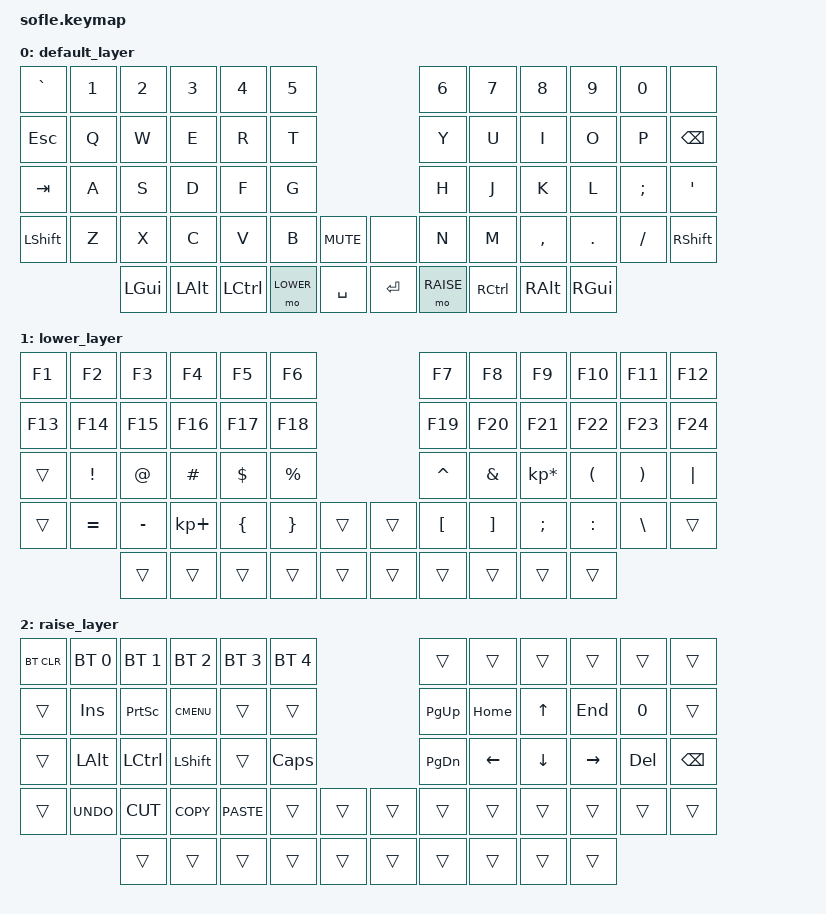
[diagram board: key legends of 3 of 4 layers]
/*
* Copyright (c) 2020 The ZMK Contributors
*
* SPDX-License-Identifier: MIT
*/

#include <behaviors.dtsi>
#include <dt-bindings/zmk/bt.h>
#include <dt-bindings/zmk/ext_power.h>
#include <dt-bindings/zmk/keys.h>
#include <dt-bindings/zmk/rgb.h>

#define BASE 0
#define LOWER 1
#define RAISE 2
#define ADJUST 3

/ {
    // Activate ADJUST layer by pressing raise and lower

    conditional_layers {
        compatible = "zmk,conditional-layers";

        adjust_layer {
            if-layers = <LOWER RAISE>;
            then-layer = <ADJUST>;
        };
    };

    keymap {
        compatible = "zmk,keymap";

        default_layer {
            // ------------------------------------------------------------------------------------------------------------
            // |  `    |  1  |  2  |  3   |  4   |  5   |                   |  6   |  7    |  8    |  9   |   0   |       |
            // |  ESC  |  Q  |  W  |  E   |  R   |  T   |                   |  Y   |  U    |  I    |  O   |   P   | BKSPC |
            // |  TAB  |  A  |  S  |  D   |  F   |  G   |                   |  H   |  J    |  K    |  L   |   ;   |   '   |
            // | SHIFT |  Z  |  X  |  C   |  V   |  B   |  MUTE  |  |       |  N   |  M    |  ,    |  .   |   /   | SHIFT |
            //               | GUI | ALT  | CTRL | LOWER|  ENTER |  | SPACE | RAISE| CTRL  | ALT   | GUI  |

            bindings = <
&kp GRAVE  &kp N1  &kp N2    &kp N3    &kp N4     &kp N5                              &kp N6     &kp N7     &kp N8     &kp N9    &kp N0    &none
&kp ESC    &kp Q   &kp W     &kp E     &kp R      &kp T                               &kp Y      &kp U      &kp I      &kp O     &kp P     &kp BSPC
&kp TAB    &kp A   &kp S     &kp D     &kp F      &kp G                               &kp H      &kp J      &kp K      &kp L     &kp SEMI  &kp SQT
&kp LSHFT  &kp Z   &kp X     &kp C     &kp V      &kp B      &kp C_MUTE    &none      &kp N      &kp M      &kp COMMA  &kp DOT   &kp FSLH  &kp RSHFT
                   &kp LGUI  &kp LALT  &kp LCTRL  &mo LOWER  &kp SPACE     &kp ENTER  &mo RAISE  &kp RCTRL  &kp RALT   &kp RGUI
            >;

            sensor-bindings = <&inc_dec_kp C_VOL_UP C_VOL_DN &inc_dec_kp PG_UP PG_DN>;
        };

        lower_layer {
            // TODO: Some binds are waiting for shifted keycode support.
            // ------------------------------------------------------------------------------------------------------------
            // |  F1   |  F2 |  F3 |  F4  |  F5  |  F6  |                   |  F7  |  F8   |  F9   |  F10 |  F11  |  F12  |
            // |  F13  | F14 | F15 | F16  | F17  | F18  |                   | F19  |  F20  |  F21  |  F22 |  F23  |  F24  |
            // |       |  !  |  @  |  #   |  $   |  %   |                   |  ^   |  &    |  *    |  (   |   )   |   |   |
            // |       |  =  |  -  |  +   |  {   |  }   |        |  |       |  [   |  ]    |  ;    |  :   |   \   |       |
            //               |     |      |      |      |        |  |       |      |       |       |      |

            bindings = <
&kp F1   &kp F2     &kp F3     &kp F4       &kp F5    &kp F6                       &kp F7     &kp F8    &kp F9           &kp F10    &kp F11   &kp F12
&kp F13  &kp F14    &kp F15    &kp F16      &kp F17   &kp F18                      &kp F19    &kp F20   &kp F21          &kp F22    &kp F23   &kp F24
&trans   &kp EXCL   &kp AT     &kp HASH     &kp DLLR  &kp PRCNT                    &kp CARET  &kp AMPS  &kp KP_MULTIPLY  &kp LPAR   &kp RPAR  &kp PIPE
&trans   &kp EQUAL  &kp MINUS  &kp KP_PLUS  &kp LBRC  &kp RBRC   &trans    &trans  &kp LBKT   &kp RBKT  &kp SEMI         &kp COLON  &kp BSLH  &trans
                    &trans     &trans       &trans    &trans     &trans    &trans  &trans     &trans    &trans           &trans
            >;

            sensor-bindings = <&inc_dec_kp C_VOL_UP C_VOL_DN &inc_dec_kp PG_UP PG_DN>;
        };

        raise_layer {
            // ------------------------------------------------------------------------------------------------------------
            // |BTCLR| BT1  | BT2  |  BT3  |  BT4  |  BT5 |                |      |      |       |      |       |       |
            // |     | INS  | PSCR | GUI   |       |      |                | PGUP | HOME |   ^   | END  |       |       |
            // |     | ALT  | CTRL | SHIFT |       | CAPS |                | PGDN |   <- |   v   |  ->  |  DEL  | BKSPC |
            // |     | UNDO | CUT  | COPY  | PASTE |      |      |  |      |      |      |       |      |       |       |
            //              |      |       |       |      |      |  |      |      |      |       |      |

            bindings = <
&bt BT_CLR  &bt BT_SEL 0  &bt BT_SEL 1  &bt BT_SEL 2  &bt BT_SEL 3  &bt BT_SEL 4                    &trans     &trans    &trans    &trans     &trans   &trans
&trans      &kp INS       &kp PSCRN     &kp K_CMENU   &trans        &trans                          &kp PG_UP  &kp HOME  &kp UP    &kp END    &kp N0   &trans
&trans      &kp LALT      &kp LCTRL     &kp LSHFT     &trans        &kp CLCK                        &kp PG_DN  &kp LEFT  &kp DOWN  &kp RIGHT  &kp DEL  &kp BSPC
&trans      &kp K_UNDO    &kp K_CUT     &kp K_COPY    &kp K_PASTE   &trans        &trans    &trans  &trans     &trans    &trans    &trans     &trans   &trans
                          &trans        &trans        &trans        &trans        &trans    &trans  &trans     &trans    &trans    &trans
            >;

            sensor-bindings = <&inc_dec_kp C_VOL_UP C_VOL_DN &inc_dec_kp PG_UP PG_DN>;
        };

        // ------------------------------------------------------------------------------------------------------------
        // |BTCLR | BT1   | BT2   |  BT3  |  BT4  |  BT5  |                |      |        |        |        |       |       |
        // |EXTPWR|RGB_HUD|RGB_HUI|RGB_SAD|RGB_SAI|RGB_EFF|                |      |        |        |        |       |       |
        // |      |RGB_BRD|RGB_BRI|       |       |       |                |M_LEFT| M_DOWN |  M_UP  | M_RIGHT|       |       |
        // |      |       |       |       |       |       |RGB_TOG| |      |SCROLL|        |        |        |       |       |
        //                |       |       |       |       |       | |      |      |        |        |        |

        Adjust_layer {
            bindings = <
&bt BT_CLR                       &bt BT_SEL 0     &bt BT_SEL 1     &bt BT_SEL 2     &bt BT_SEL 3     &bt BT_SEL 4                               &none           &none           &none         &none            &none  &none
&ext_power EXT_POWER_TOGGLE_CMD  &rgb_ug RGB_HUD  &rgb_ug RGB_HUI  &rgb_ug RGB_SAD  &rgb_ug RGB_SAI  &rgb_ug RGB_EFF                            &none           &none           &none         &none            &none  &none
&none                            &rgb_ug RGB_BRD  &rgb_ug RGB_BRI  &none            &none            &none                                      &mmv MOVE_LEFT  &mmv MOVE_DOWN  &mmv MOVE_UP  &mmv MOVE_RIGHT  &none  &none
&none                            &none            &none            &none            &none            &none            &rgb_ug RGB_TOG    &none  &msc MOVE_LEFT  &msc MOVE_DOWN  &msc MOVE_UP  &msc MOVE_RIGHT  &none  &none
                                                  &none            &none            &none            &none            &none              &none  &none           &none           &none
            >;
        };
    };
};
